# RTS5918 register map
Vendor: Realtek Semiconductor Corp.; Series: RTS5918 Series; File version: 1.00
CPU: ARMV8MML r0p0, little endian, MPU, FPU, VTOR, 3 interrupt priority bits, 8 SAU regions
Registers are 32-bit, read-write, reset 0x0 unless marked. A register's access mark holds for its fields unless they carry their own. Offsets are from the block's base; [hi:lo] are bit positions.

## T1HZ — Timer 1 Hz
Base 0x40010830
0x00 T1LDCNT — TIMER 1 Hz LOAD COUNT REGISTER
0x04 T1CRCNT (reset mask 0xFF) — TIMER 1 Hz CURRENT COUNT REGISTER
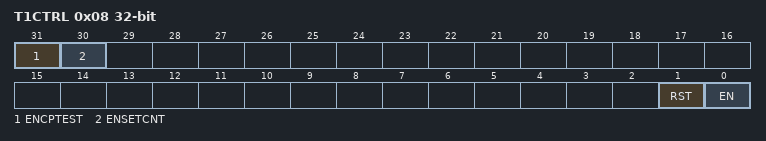
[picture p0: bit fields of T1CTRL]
0x08 T1CTRL — TIMER 1 Hz CONTROL REGISTER
  [31] ENCPTEST — Enable Timer 1 Hz CP Test
    0=NORMAL (Source is Normal Clock); 1=FAST (Source is Fast Clock)
  [30] ENSETCNT — Enable Setting Timer 1 Hz Counter
    0=NORMAL (Counting by Clock); 1=ENABLE (Enable Setting Counter)
  [1] RST — Timer 1 Hz Reset
    0=NORMAL (Out of Reset Timer 1 Hz); 1=RESET (Reset Timer 1 Hz)
  [0] EN — Timer 1 Hz Enable
    0=DISABLE (Disable Timer 1 Hz); 1=ENABLE (Enable Timer 1 Hz)
0x0C SETT1CNT — SET TIMER 1 Hz CURRENT COUNT REGISTER

## EFUSE — eFuse Controller
Base 0x40010900
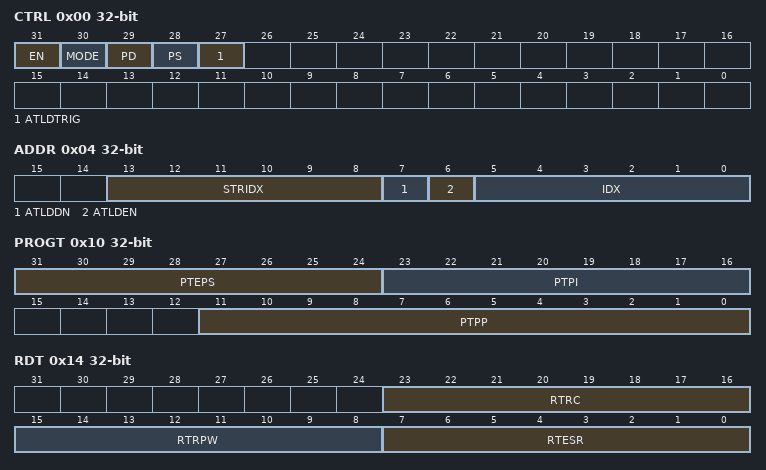
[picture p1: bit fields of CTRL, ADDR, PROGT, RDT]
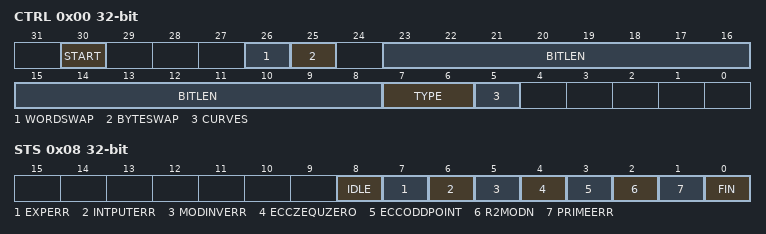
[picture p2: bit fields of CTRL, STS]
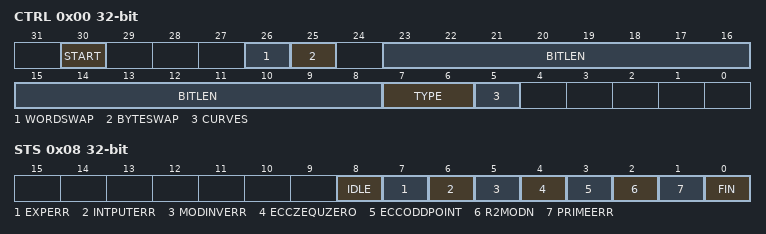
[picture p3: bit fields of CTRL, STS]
0x00 CTRL — CONTROL REGISTER
  [31] EN — Enable eFuse
    0=DISABLE (eFuse is disabled); 1=ENABLE (eFuse is enabled)
  [30] MODE — Operation Mode
    0=READ (To read data from eFuse); 1=PROGRAM (To program data into eFuse)
  [29] PD — Power Down
  [28] PS — Power Switch
  [27] ATLDTRIG — Trigger auto-load
    0=TRIG (Trigger auto-load); 1=FINISH (Auto-load completion)
0x04 ADDR — ADDRESS REGISTER
  [13:8] STRIDX — Start Index of auto-load operation
  [7] ATLDDN — Auto-load Done
  [6] ATLDEN ro — Enable Auto-load
    0=DISABLE (Auto-load operation is disabled or idle); 1=ENABLE (Auto-load operation is enabled or busy)
  [5:0] IDX — Index of eFuse
0x08 PGDATA — PROGRAM DATA REGISTER
0x0C RDDATA ro — READ DATA REGISTER
0x10 PROGT — PROGRAM TIMING REGISTER
  [31:24] PTEPS — Teps
  [23:16] PTPI — Tpi
  [11:0] PTPP — Tpp
0x14 RDT — READ TIMING REGISTER
  [23:16] RTRC — Trc
  [15:8] RTRPW — Trpw
  [7:0] RTESR — Tesr

## PKE — Lalu Public Key Engine
Base 0x40080000
0x00 CTRL — CONTROL REGISTER
  [30] START — Start PKE Function
    0=DO_NOTHING; 1=START (Start PKE function)
  [26] WORDSWAP — Word Swap Enable
    0=DISABLE (Disable word swap); 1=ENABLE (Enable word swap)
  [25] BYTESWAP — Bytes Swap Enable
    0=DISABLE (Disable byte swap); 1=ENABLE (Enable byte swap)
  [23:8] BITLEN — Precise RSA/ECC Length in Bits
  [7:6] TYPE — PKE Function Type
    0=ECC_PRIME (Use ECC prime field); 1=ECC_BINARY (Use ECC binary field); 2=RSA (Use RSA); 3=EDWARD_MONTGOMERY (Use Edwards or Montgomery curves)
  [5] CURVES
    0=EDWARD (Use Edward curves); 1=MONTGOMERY (Use Montgomery curves)
0x08 STS — STATUS REGISTER
  [8] IDLE — PKE Idle
  [7] EXPERR — No Valid Exponent
  [6] INTPUTERR — N Less Input Message For RSA
  [5] MODINVERR — Modulat Inverse Fail
  [4] ECCZEQUZERO — ECC Z = 0
  [3] ECCODDPOINT
  [2] R2MODN — R^2 Mod N Fail
  [1] PRIMEERR — Prime Check Error
  [0] FIN — ECC/RSA Operation Finish
0x14 SWAPADDR — SWAP ADDRESS REGISTER
  [11:5] ADDR — Word Swap Base Address in Word
0x10000 MMEM — PKE MAIN MEMORY
0x20000 TMEM — PKE TEMPORARY MEMORY
0x30000 IROM — PKE INSTRUCTION MEMORY

## PQC — Lalu Post Quantum Cryptography Engine
Base 0x400C0000
0x00 CTRL — CONTROL REGISTER
  [30] START — Start PKE Function
    0=DO_NOTHING; 1=START (Start PKE function)
  [26] WORDSWAP — Word Swap Enable
    0=DISABLE (Disable word swap); 1=ENABLE (Enable word swap)
  [25] BYTESWAP — Bytes Swap Enable
    0=DISABLE (Disable byte swap); 1=ENABLE (Enable byte swap)
  [23:8] BITLEN — Precise RSA/ECC Length in Bits
  [7:6] TYPE — PKE Function Type
    0=ECC_PRIME (Use ECC prime field); 1=ECC_BINARY (Use ECC binary field); 2=RSA (Use RSA); 3=EDWARD_MONTGOMERY (Use Edwards or Montgomery curves)
  [5] CURVES
    0=EDWARD (Use Edward curves); 1=MONTGOMERY (Use Montgomery curves)
0x08 STS — STATUS REGISTER
  [8] IDLE — PKE Idle
  [7] EXPERR — No Valid Exponent
  [6] INTPUTERR — N Less Input Message For RSA
  [5] MODINVERR — Modulat Inverse Fail
  [4] ECCZEQUZERO — ECC Z = 0
  [3] ECCODDPOINT
  [2] R2MODN — R^2 Mod N Fail
  [1] PRIMEERR — Prime Check Error
  [0] FIN — ECC/RSA Operation Finish
0x14 SWAPADDR — SWAP ADDRESS REGISTER
  [11:5] ADDR — Word Swap Base Address in Word
0x10000 MMEM — PKE MAIN MEMORY
0x20000 TMEM — PKE TEMPORARY MEMORY
0x30000 IROM — PKE INSTRUCTION MEMORY
